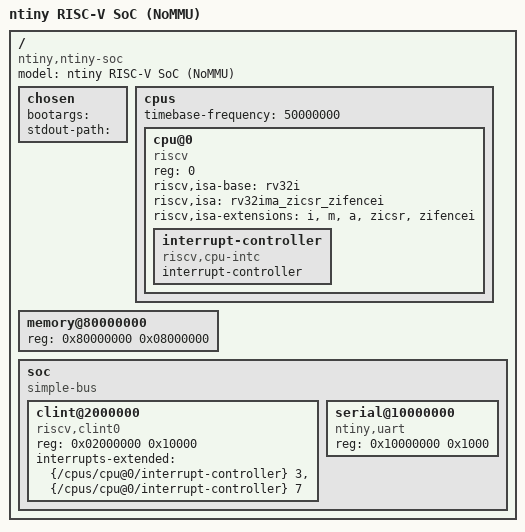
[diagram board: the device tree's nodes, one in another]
/dts-v1/;

/ {
    #address-cells = <1>;
    #size-cells = <1>;
    compatible = "ntiny,ntiny-soc";
    model = "ntiny RISC-V SoC (NoMMU)";

    chosen {
        bootargs = "";
        stdout-path = "";
    };

    cpus {
        #address-cells = <1>;
        #size-cells = <0>;
        timebase-frequency = <50000000>;

        cpu@0 {
            device_type = "cpu";
            reg = <0>;
            compatible = "riscv";
            riscv,isa-base = "rv32i";
            riscv,isa = "rv32ima_zicsr_zifencei";
            riscv,isa-extensions = "i", "m", "a", "zicsr", "zifencei";
            // No mmu-type — runs in M-mode

            interrupt-controller {
                #interrupt-cells = <1>;
                interrupt-controller;
                compatible = "riscv,cpu-intc";
                phandle = <1>;
            };
        };
    };

    memory@80000000 {
        device_type = "memory";
        reg = <0x80000000 0x08000000>;  /* 128 MB */
    };

    soc {
        #address-cells = <1>;
        #size-cells = <1>;
        compatible = "simple-bus";
        ranges;

        clint@2000000 {
            compatible = "riscv,clint0";
            reg = <0x02000000 0x10000>;
            interrupts-extended = <&{/cpus/cpu@0/interrupt-controller} 3>,
                                  <&{/cpus/cpu@0/interrupt-controller} 7>;
        };

        serial@10000000 {
            compatible = "ntiny,uart";
            reg = <0x10000000 0x1000>;
        };
    };
};
